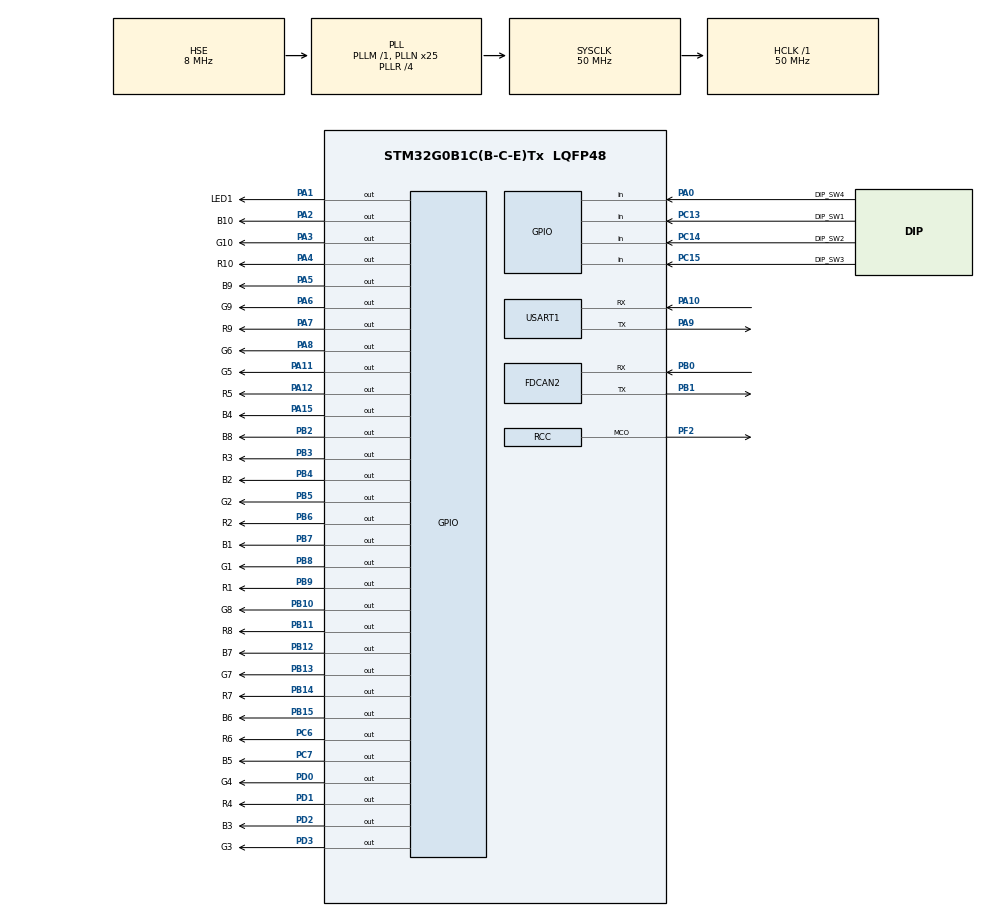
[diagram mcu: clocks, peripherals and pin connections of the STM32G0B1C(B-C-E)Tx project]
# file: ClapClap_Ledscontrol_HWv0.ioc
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FDCAN2.AutoRetransmission=ENABLE
FDCAN2.CalculateBaudRateNominal=500000
FDCAN2.CalculateTimeBitNominal=2000
FDCAN2.CalculateTimeQuantumNominal=20.0
FDCAN2.DataSyncJumpWidth=4
FDCAN2.DataTimeSeg1=5
FDCAN2.DataTimeSeg2=4
FDCAN2.NominalPrescaler=1
FDCAN2.NominalSyncJumpWidth=16
FDCAN2.NominalTimeSeg1=86
FDCAN2.NominalTimeSeg2=13
FDCAN2.StdFiltersNbr=1
FDCAN2.TransmitPause=ENABLE
IWDG.Reload=1599
Mcu.Family=STM32G0
Mcu.Name=STM32G0B1C(B-C-E)Tx
Mcu.Package=LQFP48
NVIC.TIM14_IRQn=true\:1\:0\:true\:false\:true\:true\:true\:true
NVIC.TIM16_FDCAN_IT0_IRQn=true\:2\:0\:true\:false\:true\:true\:true\:true
NVIC.TIM17_FDCAN_IT1_IRQn=true\:2\:0\:true\:false\:true\:true\:true\:true
NVIC.TIM7_LPTIM2_IRQn=true\:0\:0\:true\:false\:true\:true\:true\:true
NVIC.USART1_IRQn=true\:2\:0\:true\:false\:true\:true\:true\:true
PA0.GPIO_Label=DIP_SW4
PA0.Signal=GPIO_Input
PA1.GPIO_Label=LED1
PA1.Signal=GPIO_Output
PA10.Mode=Asynchronous
PA10.Signal=USART1_RX
PA11\ [PA9].GPIO_Label=G5
PA11\ [PA9].Signal=GPIO_Output
PA12\ [PA10].GPIO_Label=R5
PA12\ [PA10].Signal=GPIO_Output
PA13.GPIO_Label=SWCLK
PA13.Mode=Serial_Wire
PA13.Signal=SYS_SWDIO
PA14-BOOT0.GPIO_Label=SWDIO
PA14-BOOT0.Mode=Serial_Wire
PA14-BOOT0.Signal=SYS_SWCLK
PA15.GPIO_Label=B4
PA15.Signal=GPIO_Output
PA2.GPIO_Label=B10
PA2.Signal=GPIO_Output
PA3.GPIO_Label=G10
PA3.Signal=GPIO_Output
PA4.GPIO_Label=R10
PA4.Signal=GPIO_Output
PA5.GPIO_Label=B9
PA5.Signal=GPIO_Output
PA6.GPIO_Label=G9
PA6.Signal=GPIO_Output
PA7.GPIO_Label=R9
PA7.Signal=GPIO_Output
PA8.GPIO_Label=G6
PA8.Signal=GPIO_Output
PA9.Mode=Asynchronous
PA9.Signal=USART1_TX
PB0.Mode=FDCAN_Activate
PB0.Signal=FDCAN2_RX
PB1.Mode=FDCAN_Activate
PB1.Signal=FDCAN2_TX
PB10.GPIO_Label=G8
PB10.Signal=GPIO_Output
PB11.GPIO_Label=R8
PB11.Signal=GPIO_Output
PB12.GPIO_Label=B7
PB12.Signal=GPIO_Output
PB13.GPIO_Label=G7
PB13.Signal=GPIO_Output
PB14.GPIO_Label=R7
PB14.Signal=GPIO_Output
PB15.GPIO_Label=B6
PB15.Signal=GPIO_Output
PB2.GPIO_Label=B8
PB2.Signal=GPIO_Output
PB3.GPIO_Label=R3
PB3.Signal=GPIO_Output
PB4.GPIO_Label=B2
PB4.Signal=GPIO_Output
PB5.GPIO_Label=G2
PB5.Signal=GPIO_Output
PB6.GPIO_Label=R2
PB6.Signal=GPIO_Output
PB7.GPIO_Label=B1
PB7.Signal=GPIO_Output
PB8.GPIO_Label=G1
PB8.Signal=GPIO_Output
PB9.GPIO_Label=R1
PB9.Signal=GPIO_Output
PC13.GPIO_Label=DIP_SW1
PC13.Signal=GPIO_Input
PC14-OSC32_IN\ (PC14).GPIO_Label=DIP_SW2
PC14-OSC32_IN\ (PC14).Signal=GPIO_Input
PC15-OSC32_OUT\ (PC15).GPIO_Label=DIP_SW3
PC15-OSC32_OUT\ (PC15).Signal=GPIO_Input
PC6.GPIO_Label=R6
PC6.Signal=GPIO_Output
PC7.GPIO_Label=B5
PC7.Signal=GPIO_Output
PD0.GPIO_Label=G4
PD0.Signal=GPIO_Output
PD1.GPIO_Label=R4
PD1.Signal=GPIO_Output
PD2.GPIO_Label=B3
PD2.Signal=GPIO_Output
PD3.GPIO_Label=G3
PD3.Signal=GPIO_Output
PF0-OSC_IN\ (PF0).Mode=HSE-External-Oscillator
PF0-OSC_IN\ (PF0).Signal=RCC_OSC_IN
PF1-OSC_OUT\ (PF1).Mode=HSE-External-Oscillator
PF1-OSC_OUT\ (PF1).Signal=RCC_OSC_OUT
PF2-NRST.Mode=Clock-out
PF2-NRST.Signal=RCC_MCO
ProjectManager.HeapSize=0x200
ProjectManager.StackSize=0x400
ProjectManager.TargetToolchain=STM32CubeIDE
RCC.ADCFreq_Value=50000000
RCC.AHBFreq_Value=50000000
RCC.CortexFreq_Value=50000000
RCC.EXTERNAL_CLOCK_VALUE=48000
RCC.HCLKFreq_Value=50000000
RCC.HSE_VALUE=8000000
RCC.HSI48_VALUE=48000000
RCC.HSI_VALUE=16000000
RCC.LSE_VALUE=32768
RCC.PLLN=25
RCC.PLLP=RCC_PLLP_DIV5
RCC.PLLR=RCC_PLLR_DIV4
RCC.PLLSourceVirtual=RCC_PLLSOURCE_HSE
RCC.SYSCLKFreq_VALUE=50000000
RCC.SYSCLKSource=RCC_SYSCLKSOURCE_PLLCLK
RCC.USBFreq_Value=48000000
RCC.VCOOutputFreq_Value=200000000
TIM14.AutoReloadPreload=TIM_AUTORELOAD_PRELOAD_ENABLE
TIM14.Period=50000-1
TIM7.AutoReloadPreload=TIM_AUTORELOAD_PRELOAD_ENABLE
TIM7.Period=5000-1
USART1.VirtualMode-Asynchronous=VM_ASYNC
VP_IWDG_VS_IWDG.Mode=IWDG_Activate
VP_RTC_VS_RTC_Activate.Mode=RTC_Enabled
VP_SYS_VS_DBSignals.Mode=DisableDeadBatterySignals
VP_TIM14_VS_ClockSourceINT.Mode=Enable_Timer
VP_TIM6_VS_ClockSourceINT.Mode=Enable_Timer
VP_TIM7_VS_ClockSourceINT.Mode=Enable_Timer
board=custom

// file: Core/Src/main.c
/* USER CODE BEGIN Header */
/**
  ******************************************************************************
  * @file           : main.c
  * @brief          : Main program body
  ******************************************************************************
  * @attention
  *
  * Copyright (c) 2024 STMicroelectronics.
  * All rights reserved.
  *
  * This software is licensed under terms that can be found in the LICENSE file
  * in the root directory of this software component.
  * If no LICENSE file comes with this software, it is provided AS-IS.
  *
  ******************************************************************************
  */

/*
 *
 *
 *  Created on: Oct 20, 2024
 *      Author: Xavier Alsina
 *
Disclaimer:
This project, including all associated documentation and code, is provided "as is," without warranty of any kind, express or implied, including but not limited to the warranties of merchantability, fitness for a particular purpose, or non-infringement.

In no event shall the authors or copyright holders be liable for any claim, damages, or other liability, whether in an action of contract, tort, or otherwise, arising from, out of, or in connection with the project or the use or other dealings in the project.

The code and documentation generated as part of this project are released under the following terms:
1.	Use and Distribution: You are free to use, modify, and distribute the code and documentation in any medium, provided that proper attribution to the original authors is given.
2.	Non-Commercial Use: This project may be used for personal, educational, or non-commercial purposes. If you intend to use any part of this project to generate revenue or for commercial purposes, explicit written permission from the author is required.
3.	No Warranty: The authors make no guarantees about the correctness, reliability, or stability of the code. It is your responsibility to test and verify that the code functions as required in your environment.
4.	Liability: Under no circumstances shall the authors or contributors be held liable for any direct, indirect, incidental, special, or consequential damages arising out of the use of the code or documentation.
5.	Contribution: Any contributions made to this project, including pull requests, are assumed to be provided under the same license and terms as the original project.
6.	Licensing: This project may be subject to additional licensing terms and conditions, particularly if integrating with third-party libraries or systems. It is the user's responsibility to ensure compliance with any such licenses.
 *
 */

/* USER CODE END Header */
#include "main.h"
#include "MiddleLayer\CC_ML.h"

FDCAN_HandleTypeDef hfdcan2;

IWDG_HandleTypeDef hiwdg;

RTC_HandleTypeDef hrtc;

TIM_HandleTypeDef htim6;
TIM_HandleTypeDef htim7;
TIM_HandleTypeDef htim14;

UART_HandleTypeDef huart1;

void SystemClock_Config(void);
static void MX_GPIO_Init(void);
static void MX_FDCAN2_Init(void);
static void MX_TIM14_Init(void);
static void MX_USART1_UART_Init(void);
static void MX_TIM6_Init(void);
static void MX_TIM7_Init(void);
static void MX_IWDG_Init(void);
static void MX_RTC_Init(void);

int main(void)
{

  /* MCU Configuration--------------------------------------------------------*/

  /* Reset of all peripherals, Initializes the Flash interface and the Systick. */
  HAL_Init();

  /* Configure the system clock */
  SystemClock_Config();

  /* Initialize all configured peripherals */
  MX_GPIO_Init();
  MX_FDCAN2_Init();
  MX_TIM14_Init();
  MX_USART1_UART_Init();
  MX_TIM6_Init();
  MX_TIM7_Init();
  MX_IWDG_Init();
  MX_RTC_Init();
  /* USER CODE BEGIN 2 */

  CC_APP_SetBoardParam(&CC_APP_BoardData);						//Board's characteristics and parameters setting
  CC_ML_InitRTC(&hrtc);											//Init peripheral
  CC_ML_SetDefaultRTC(&hrtc);									//Set a default date and time to the RTC

  //SoftPWM for strip leds initialization
  CC_LEDPWM_Init(&CC_LEDPWM_Strip);	  							//Strip-leds handler initialization
  CC_ML_StartSoftPwmBasetimeAndInterrupts();					//Soft-PWM timer generation initialization
  //Schedulers initialization
  CC_SCHDLR_InitScheduler(&CC_SCHDLR_MainScheduler);			//Fast tasks loading
  CC_SCHDLR_InitNestedScheduler(&CC_SCHDLR_NestedScheduler);	//Tasks loading onto nested scheduler
  CC_ML_StartScheduler();										//Schedulers on
  //Serial receive initialization
  CC_ML_EnableRxIntUart();										//UART Rx interruptions enabled
  //CAN initialization
  CC_ML_InitCan();												//CAN initialization
  CC_ML_StartCan();												//CAN ready to send
  CC_ML_EnableCanRxInt();										//CAN Rx interruptions enabled
  /* USER CODE END 2 */

  /* Infinite loop */
  while (1)
  {

  }
}

void SystemClock_Config(void)
{
  RCC_OscInitTypeDef RCC_OscInitStruct = {0};
  RCC_ClkInitTypeDef RCC_ClkInitStruct = {0};

  /** Configure the main internal regulator output voltage
  */
  HAL_PWREx_ControlVoltageScaling(PWR_REGULATOR_VOLTAGE_SCALE1);

  /** Initializes the RCC Oscillators according to the specified parameters
  * in the RCC_OscInitTypeDef structure.
  */
  RCC_OscInitStruct.OscillatorType = RCC_OSCILLATORTYPE_LSI|RCC_OSCILLATORTYPE_HSE;
  RCC_OscInitStruct.HSEState = RCC_HSE_ON;
  RCC_OscInitStruct.LSIState = RCC_LSI_ON;
  RCC_OscInitStruct.PLL.PLLState = RCC_PLL_ON;
  RCC_OscInitStruct.PLL.PLLSource = RCC_PLLSOURCE_HSE;
  RCC_OscInitStruct.PLL.PLLM = RCC_PLLM_DIV1;
  RCC_OscInitStruct.PLL.PLLN = 25;
  RCC_OscInitStruct.PLL.PLLP = RCC_PLLP_DIV5;
  RCC_OscInitStruct.PLL.PLLQ = RCC_PLLQ_DIV2;
  RCC_OscInitStruct.PLL.PLLR = RCC_PLLR_DIV4;
  if (HAL_RCC_OscConfig(&RCC_OscInitStruct) != HAL_OK)
  {
    Error_Handler();
  }

  /** Initializes the CPU, AHB and APB buses clocks
  */
  RCC_ClkInitStruct.ClockType = RCC_CLOCKTYPE_HCLK|RCC_CLOCKTYPE_SYSCLK
                              |RCC_CLOCKTYPE_PCLK1;
  RCC_ClkInitStruct.SYSCLKSource = RCC_SYSCLKSOURCE_PLLCLK;
  RCC_ClkInitStruct.AHBCLKDivider = RCC_SYSCLK_DIV1;
  RCC_ClkInitStruct.APB1CLKDivider = RCC_HCLK_DIV1;

  if (HAL_RCC_ClockConfig(&RCC_ClkInitStruct, FLASH_LATENCY_2) != HAL_OK)
  {
    Error_Handler();
  }
  HAL_RCC_MCOConfig(RCC_MCO_PF2, RCC_MCO1SOURCE_SYSCLK, RCC_MCODIV_1);
}

static void MX_FDCAN2_Init(void)
{

  hfdcan2.Instance = FDCAN2;
  hfdcan2.Init.ClockDivider = FDCAN_CLOCK_DIV1;
  hfdcan2.Init.FrameFormat = FDCAN_FRAME_CLASSIC;
  hfdcan2.Init.Mode = FDCAN_MODE_NORMAL;
  hfdcan2.Init.AutoRetransmission = ENABLE;
  hfdcan2.Init.TransmitPause = ENABLE;
  hfdcan2.Init.ProtocolException = DISABLE;
  hfdcan2.Init.NominalPrescaler = 1;
  hfdcan2.Init.NominalSyncJumpWidth = 16;
  hfdcan2.Init.NominalTimeSeg1 = 86;
  hfdcan2.Init.NominalTimeSeg2 = 13;
  hfdcan2.Init.DataPrescaler = 1;
  hfdcan2.Init.DataSyncJumpWidth = 4;
  hfdcan2.Init.DataTimeSeg1 = 5;
  hfdcan2.Init.DataTimeSeg2 = 4;
  hfdcan2.Init.StdFiltersNbr = 1;
  hfdcan2.Init.ExtFiltersNbr = 0;
  hfdcan2.Init.TxFifoQueueMode = FDCAN_TX_FIFO_OPERATION;
  if (HAL_FDCAN_Init(&hfdcan2) != HAL_OK)
  {
    Error_Handler();
  }

}

static void MX_IWDG_Init(void)
{

  hiwdg.Instance = IWDG;
  hiwdg.Init.Prescaler = IWDG_PRESCALER_4;
  hiwdg.Init.Window = 4095;
  hiwdg.Init.Reload = 1599;
  if (HAL_IWDG_Init(&hiwdg) != HAL_OK)
  {
    Error_Handler();
  }

}

static void MX_RTC_Init(void)
{

  /** Initialize RTC Only
  */
  hrtc.Instance = RTC;
  hrtc.Init.HourFormat = RTC_HOURFORMAT_24;
  hrtc.Init.AsynchPrediv = 127;
  hrtc.Init.SynchPrediv = 255;
  hrtc.Init.OutPut = RTC_OUTPUT_DISABLE;
  hrtc.Init.OutPutRemap = RTC_OUTPUT_REMAP_NONE;
  hrtc.Init.OutPutPolarity = RTC_OUTPUT_POLARITY_HIGH;
  hrtc.Init.OutPutType = RTC_OUTPUT_TYPE_OPENDRAIN;
  hrtc.Init.OutPutPullUp = RTC_OUTPUT_PULLUP_NONE;
  if (HAL_RTC_Init(&hrtc) != HAL_OK)
  {
    Error_Handler();
  }

}

static void MX_TIM6_Init(void)
{

  TIM_MasterConfigTypeDef sMasterConfig = {0};

  htim6.Instance = TIM6;
  htim6.Init.Prescaler = 0;
  htim6.Init.CounterMode = TIM_COUNTERMODE_UP;
  htim6.Init.Period = 65535;
  htim6.Init.AutoReloadPreload = TIM_AUTORELOAD_PRELOAD_DISABLE;
  if (HAL_TIM_Base_Init(&htim6) != HAL_OK)
  {
    Error_Handler();
  }
  sMasterConfig.MasterOutputTrigger = TIM_TRGO_RESET;
  sMasterConfig.MasterSlaveMode = TIM_MASTERSLAVEMODE_DISABLE;
  if (HAL_TIMEx_MasterConfigSynchronization(&htim6, &sMasterConfig) != HAL_OK)
  {
    Error_Handler();
  }

}

static void MX_TIM7_Init(void)
{

  TIM_MasterConfigTypeDef sMasterConfig = {0};

  htim7.Instance = TIM7;
  htim7.Init.Prescaler = 0;
  htim7.Init.CounterMode = TIM_COUNTERMODE_UP;
  htim7.Init.Period = 5000-1;
  htim7.Init.AutoReloadPreload = TIM_AUTORELOAD_PRELOAD_ENABLE;
  if (HAL_TIM_Base_Init(&htim7) != HAL_OK)
  {
    Error_Handler();
  }
  sMasterConfig.MasterOutputTrigger = TIM_TRGO_RESET;
  sMasterConfig.MasterSlaveMode = TIM_MASTERSLAVEMODE_DISABLE;
  if (HAL_TIMEx_MasterConfigSynchronization(&htim7, &sMasterConfig) != HAL_OK)
  {
    Error_Handler();
  }

}

static void MX_TIM14_Init(void)
{

  htim14.Instance = TIM14;
  htim14.Init.Prescaler = 0;
  htim14.Init.CounterMode = TIM_COUNTERMODE_UP;
  htim14.Init.Period = 50000-1;
  htim14.Init.ClockDivision = TIM_CLOCKDIVISION_DIV1;
  htim14.Init.AutoReloadPreload = TIM_AUTORELOAD_PRELOAD_ENABLE;
  if (HAL_TIM_Base_Init(&htim14) != HAL_OK)
  {
    Error_Handler();
  }

}

static void MX_USART1_UART_Init(void)
{

  huart1.Instance = USART1;
  huart1.Init.BaudRate = 115200;
  huart1.Init.WordLength = UART_WORDLENGTH_8B;
  huart1.Init.StopBits = UART_STOPBITS_1;
  huart1.Init.Parity = UART_PARITY_NONE;
  huart1.Init.Mode = UART_MODE_TX_RX;
  huart1.Init.HwFlowCtl = UART_HWCONTROL_NONE;
  huart1.Init.OverSampling = UART_OVERSAMPLING_16;
  huart1.Init.OneBitSampling = UART_ONE_BIT_SAMPLE_DISABLE;
  huart1.Init.ClockPrescaler = UART_PRESCALER_DIV1;
  huart1.AdvancedInit.AdvFeatureInit = UART_ADVFEATURE_NO_INIT;
  if (HAL_UART_Init(&huart1) != HAL_OK)
  {
    Error_Handler();
  }
  if (HAL_UARTEx_SetTxFifoThreshold(&huart1, UART_TXFIFO_THRESHOLD_1_8) != HAL_OK)
  {
    Error_Handler();
  }
  if (HAL_UARTEx_SetRxFifoThreshold(&huart1, UART_RXFIFO_THRESHOLD_1_8) != HAL_OK)
  {
    Error_Handler();
  }
  if (HAL_UARTEx_DisableFifoMode(&huart1) != HAL_OK)
  {
    Error_Handler();
  }

}

static void MX_GPIO_Init(void)
{
  GPIO_InitTypeDef GPIO_InitStruct = {0};

  /* GPIO Ports Clock Enable */
  __HAL_RCC_GPIOC_CLK_ENABLE();
  __HAL_RCC_GPIOF_CLK_ENABLE();
  __HAL_RCC_GPIOA_CLK_ENABLE();
  __HAL_RCC_GPIOB_CLK_ENABLE();
  __HAL_RCC_GPIOD_CLK_ENABLE();

  /*Configure GPIO pin Output Level */
  HAL_GPIO_WritePin(GPIOA, LED1_Pin|B10_Pin|G10_Pin|R10_Pin
                          |B9_Pin|G9_Pin|R9_Pin|G6_Pin
                          |G5_Pin|R5_Pin|B4_Pin, GPIO_PIN_RESET);

  /*Configure GPIO pin Output Level */
  HAL_GPIO_WritePin(GPIOB, B8_Pin|G8_Pin|R8_Pin|B7_Pin
                          |G7_Pin|R7_Pin|B6_Pin|R3_Pin
                          |B2_Pin|G2_Pin|R2_Pin|B1_Pin
                          |G1_Pin|R1_Pin, GPIO_PIN_RESET);

  /*Configure GPIO pin Output Level */
  HAL_GPIO_WritePin(GPIOC, R6_Pin|B5_Pin, GPIO_PIN_RESET);

  /*Configure GPIO pin Output Level */
  HAL_GPIO_WritePin(GPIOD, G4_Pin|R4_Pin|B3_Pin|G3_Pin, GPIO_PIN_RESET);

  /*Configure GPIO pins : DIP_SW1_Pin DIP_SW2_Pin DIP_SW3_Pin */
  GPIO_InitStruct.Pin = DIP_SW1_Pin|DIP_SW2_Pin|DIP_SW3_Pin;
  GPIO_InitStruct.Mode = GPIO_MODE_INPUT;
  GPIO_InitStruct.Pull = GPIO_NOPULL;
  HAL_GPIO_Init(GPIOC, &GPIO_InitStruct);

  /*Configure GPIO pin : PF2 */
  GPIO_InitStruct.Pin = GPIO_PIN_2;
  GPIO_InitStruct.Mode = GPIO_MODE_AF_PP;
  GPIO_InitStruct.Pull = GPIO_NOPULL;
  GPIO_InitStruct.Speed = GPIO_SPEED_FREQ_LOW;
  GPIO_InitStruct.Alternate = GPIO_AF0_MCO;
  HAL_GPIO_Init(GPIOF, &GPIO_InitStruct);

  /*Configure GPIO pin : DIP_SW4_Pin */
  GPIO_InitStruct.Pin = DIP_SW4_Pin;
  GPIO_InitStruct.Mode = GPIO_MODE_INPUT;
  GPIO_InitStruct.Pull = GPIO_NOPULL;
  HAL_GPIO_Init(DIP_SW4_GPIO_Port, &GPIO_InitStruct);

  /*Configure GPIO pins : LED1_Pin B10_Pin G10_Pin R10_Pin
                           B9_Pin G9_Pin R9_Pin G6_Pin
                           G5_Pin R5_Pin B4_Pin */
  GPIO_InitStruct.Pin = LED1_Pin|B10_Pin|G10_Pin|R10_Pin
                          |B9_Pin|G9_Pin|R9_Pin|G6_Pin
                          |G5_Pin|R5_Pin|B4_Pin;
  GPIO_InitStruct.Mode = GPIO_MODE_OUTPUT_PP;
  GPIO_InitStruct.Pull = GPIO_NOPULL;
  GPIO_InitStruct.Speed = GPIO_SPEED_FREQ_LOW;
  HAL_GPIO_Init(GPIOA, &GPIO_InitStruct);

  /*Configure GPIO pins : B8_Pin G8_Pin R8_Pin B7_Pin
                           G7_Pin R7_Pin B6_Pin R3_Pin
                           B2_Pin G2_Pin R2_Pin B1_Pin
                           G1_Pin R1_Pin */
  GPIO_InitStruct.Pin = B8_Pin|G8_Pin|R8_Pin|B7_Pin
                          |G7_Pin|R7_Pin|B6_Pin|R3_Pin
                          |B2_Pin|G2_Pin|R2_Pin|B1_Pin
                          |G1_Pin|R1_Pin;
  GPIO_InitStruct.Mode = GPIO_MODE_OUTPUT_PP;
  GPIO_InitStruct.Pull = GPIO_NOPULL;
  GPIO_InitStruct.Speed = GPIO_SPEED_FREQ_LOW;
  HAL_GPIO_Init(GPIOB, &GPIO_InitStruct);

  /*Configure GPIO pins : R6_Pin B5_Pin */
  GPIO_InitStruct.Pin = R6_Pin|B5_Pin;
  GPIO_InitStruct.Mode = GPIO_MODE_OUTPUT_PP;
  GPIO_InitStruct.Pull = GPIO_NOPULL;
  GPIO_InitStruct.Speed = GPIO_SPEED_FREQ_LOW;
  HAL_GPIO_Init(GPIOC, &GPIO_InitStruct);

  /*Configure GPIO pins : G4_Pin R4_Pin B3_Pin G3_Pin */
  GPIO_InitStruct.Pin = G4_Pin|R4_Pin|B3_Pin|G3_Pin;
  GPIO_InitStruct.Mode = GPIO_MODE_OUTPUT_PP;
  GPIO_InitStruct.Pull = GPIO_NOPULL;
  GPIO_InitStruct.Speed = GPIO_SPEED_FREQ_LOW;
  HAL_GPIO_Init(GPIOD, &GPIO_InitStruct);

}

void Error_Handler(void)
{
  __disable_irq();
  while (1)
  {
  }
}
